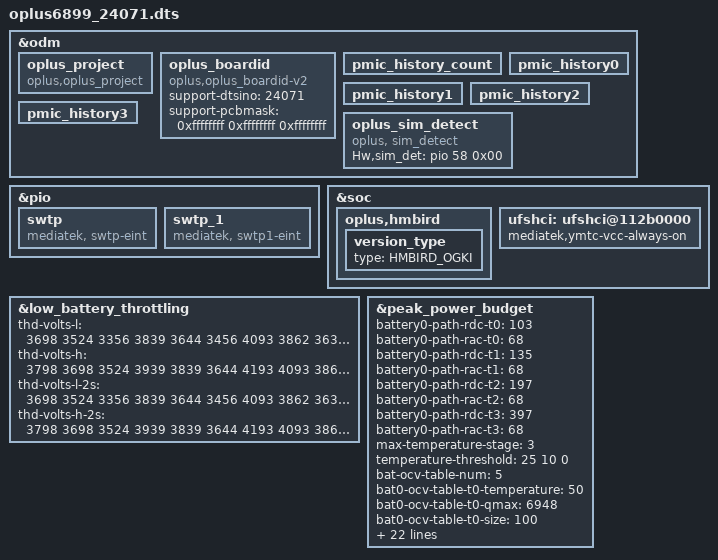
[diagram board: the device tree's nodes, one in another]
// SPDX-License-Identifier: (GPL-2.0 OR MIT)
/*
 * Copyright (C) 2022 MediaTek Inc.
 */
#include "k6899v1_64.dts"

/* #ifdef OPLUS_FEATURE_CHG_BASIC */
/* Add for 24P charge device-tree */
#include "mediatek/oplus_chg/oplus_charge_24071.dtsi"
/* #endif */

/* #ifdef OPLUS_FEATURE_CHG_BASIC */
#include "mediatek/oplus_misc_24071.dtsi"
/* #endif */

/* #ifdef OPLUS_FEATURE_SENSOR */
#include "mediatek/oplus_sensor_24071.dtsi"
/* #endif */

/* #ifdef OPLUS_DISPLAY_FEATURE */
#include "mediatek/oplus-display/mt6899-zhuque-24071-display-overlay.dtsi"
/* #endif */

/* Add for ZhuqueC1 pt device-tree */
#include "mediatek/oplus_pt_24071.dtsi"
/* #endif */

&odm {
	/*OPLUS_FEATURE_OEM_OCDT oppo project start */
	oplus_project:oplus_project {
		compatible = "oplus,oplus_project";
    };

    oplus_boardid:oplus_boardid {
        compatible = "oplus,oplus_boardid-v2";
        support-dtsino=<24071>;//only one u32
        /*first one is low 32bit, last one is highest 32bit, must be 32-bit for 4gpios*/
        support-pcbmask=<0xffffffff 0xffffffff 0xffffffff>;
    };

	pmic_history_count:pmic_history_count {
	};
	pmic_history0:pmic_history0 {
	};
	pmic_history1:pmic_history1 {
	};
	pmic_history2:pmic_history2 {
	};
	pmic_history3:pmic_history3 {
	};
};

&odm {
/* Add for sim detect */
    oplus_sim_detect {
        compatible = "oplus, sim_detect";
        Hw,sim_det = <&pio 58 0x00>;
    };
};

&pio {
	//#ifdef OPLUS_VENDOR_SWTP
	swtp: swtp {
		compatible = "mediatek, swtp-eint";
	};
	 swtp_1: swtp_1 {
        compatible = "mediatek, swtp1-eint";
    };
	//#endif  /*OPLUS_VENDOR_SWTP*/
};

&soc {
    //#ifdef CONFIG_HMBIRD_SCHED
    oplus,hmbird {
        version_type {
            type = "HMBIRD_OGKI";
        };
    };
    //#endif /* CONFIG_HMBIRD_SCHED */
};

&low_battery_throttling {
	thd-volts-l = <
			3698 3524 3356
			3839 3644 3456
			4093 3862 3636
			4400 4139 3784>;
	thd-volts-h = <
			3798 3698 3524
			3939 3839 3644
			4193 4093 3862
			4500 4400 4139>;
	thd-volts-l-2s = <
			3698 3524 3356
			3839 3644 3456
			4093 3862 3636
			4400 4139 3784>;
	thd-volts-h-2s = <
			3798 3698 3524
			3939 3839 3644
			4193 4093 3862
			4500 4400 4139>;
};

&peak_power_budget {
	battery0-path-rdc-t0 = <103>;
	battery0-path-rac-t0 = <68>;
	battery0-path-rdc-t1 = <135>;
	battery0-path-rac-t1 = <68>;
	battery0-path-rdc-t2 = <197>;
	battery0-path-rac-t2 = <68>;
	battery0-path-rdc-t3 = <397>;
	battery0-path-rac-t3 = <68>;
	max-temperature-stage = <3>;
	temperature-threshold = <25 10 0>;

	bat-ocv-table-num = <5>;

	bat0-ocv-table-t0-temperature = <50>;
	bat0-ocv-table-t0-qmax = <6948>;
	bat0-ocv-table-t0-size = <100>;
	bat0-ocv-table-t0 = <
		0       44828   0
		719     44597   0
		1438    44430   0
		2156    44298   0
		2875    44184   0
		3594    44074   0
		4313    43968   0
		5031    43860   0
		5750    43754   0
		6469    43642   0
		7188    43530   0
		7906    43418   0
		8625    43300   0
		9344    43184   0
		10063   43065   0
		10781   42937   0
		11500   42816   0
		12219   42688   0
		12938   42561   0
		13656   42434   0
		14375   42306   0
		15094   42171   0
		15813   42042   0
		16531   41914   0
		17250   41786   0
		17969   41664   0
		18688   41537   0
		19407   41418   0
		20125   41298   0
		20844   41173   0
		21563   41057   0
		22282   40941   0
		23000   40830   0
		23719   40718   0
		24438   40605   0
		25157   40495   0
		25875   40392   0
		26594   40288   0
		27313   40186   0
		28032   40092   0
		28750   39992   0
		29469   39894   0
		30188   39787   0
		30907   39660   0
		31625   39488   0
		32344   39330   0
		33063   39220   0
		33782   39128   0
		34501   39049   0
		35219   38971   0
		35938   38896   0
		36657   38826   0
		37376   38767   0
		38094   38705   0
		38813   38643   0
		39532   38583   0
		40251   38526   0
		40969   38476   0
		41688   38421   0
		42407   38372   0
		43126   38326   0
		43844   38278   0
		44563   38237   0
		45282   38193   0
		46001   38155   0
		46719   38114   0
		47438   38078   0
		48157   38041   0
		48876   37995   0
		49594   37950   0
		50313   37868   0
		51032   37779   0
		51751   37704   0
		52470   37655   0
		53188   37599   0
		53907   37544   0
		54626   37490   0
		55345   37444   0
		56063   37395   0
		56782   37351   0
		57501   37302   0
		58220   37235   0
		58938   37159   0
		59657   37092   0
		60376   37025   0
		61095   36933   0
		61813   36875   0
		62532   36859   0
		63251   36848   0
		63970   36826   0
		64688   36808   0
		65407   36767   0
		66126   36619   0
		66845   36235   0
		67564   35698   0
		68282   34998   0
		69001   34011   0
		69720   32471   0
		70439   32471   0
		71157   32471   0>;

	bat0-ocv-table-t1-temperature = <25>;
	bat0-ocv-table-t1-qmax = <7090>;
	bat0-ocv-table-t1-size = <100>;
	bat0-ocv-table-t1 = <
		0       44934   0
		719     44701   0
		1438    44536   0
		2156    44405   0
		2875    44289   0
		3594    44185   0
		4313    44078   0
		5031    43962   0
		5750    43856   0
		6469    43751   0
		7188    43639   0
		7906    43529   0
		8625    43412   0
		9344    43310   0
		10063   43193   0
		10781   43069   0
		11500   42946   0
		12219   42820   0
		12938   42695   0
		13656   42566   0
		14375   42438   0
		15094   42310   0
		15813   42179   0
		16531   42048   0
		17250   41927   0
		17969   41799   0
		18688   41669   0
		19407   41548   0
		20125   41422   0
		20844   41303   0
		21563   41187   0
		22282   41068   0
		23000   40951   0
		23719   40843   0
		24438   40728   0
		25157   40622   0
		25875   40513   0
		26594   40409   0
		27313   40309   0
		28032   40202   0
		28750   40102   0
		29469   40002   0
		30188   39901   0
		30907   39793   0
		31625   39673   0
		32344   39523   0
		33063   39361   0
		33782   39229   0
		34501   39130   0
		35219   39039   0
		35938   38967   0
		36657   38896   0
		37376   38830   0
		38094   38767   0
		38813   38706   0
		39532   38650   0
		40251   38590   0
		40969   38536   0
		41688   38485   0
		42407   38434   0
		43126   38389   0
		43844   38345   0
		44563   38297   0
		45282   38257   0
		46001   38218   0
		46719   38185   0
		47438   38147   0
		48157   38108   0
		48876   38078   0
		49594   38044   0
		50313   38001   0
		51032   37967   0
		51751   37923   0
		52470   37871   0
		53188   37815   0
		53907   37770   0
		54626   37716   0
		55345   37662   0
		56063   37614   0
		56782   37580   0
		57501   37535   0
		58220   37493   0
		58938   37441   0
		59657   37373   0
		60376   37307   0
		61095   37232   0
		61813   37163   0
		62532   37070   0
		63251   37007   0
		63970   36991   0
		64688   36975   0
		65407   36956   0
		66126   36936   0
		66845   36898   0
		67564   36780   0
		68282   36403   0
		69001   35859   0
		69720   35131   0
		70439   34082   0
		71157   32223   0>;

	bat0-ocv-table-t2-temperature = <10>;
	bat0-ocv-table-t2-qmax = <7056>;
	bat0-ocv-table-t2-size = <100>;
	bat0-ocv-table-t2 = <
		0       44822   0
		719     44608   0
		1438    44459   0
		2156    44332   0
		2875    44228   0
		3594    44128   0
		4313    44021   0
		5031    43921   0
		5750    43821   0
		6469    43707   0
		7188    43601   0
		7906    43495   0
		8625    43378   0
		9344    43260   0
		10063   43146   0
		10781   43019   0
		11500   42895   0
		12219   42767   0
		12938   42638   0
		13656   42509   0
		14375   42380   0
		15094   42247   0
		15813   42122   0
		16531   41987   0
		17250   41866   0
		17969   41735   0
		18688   41609   0
		19407   41484   0
		20125   41361   0
		20844   41240   0
		21563   41122   0
		22282   41004   0
		23000   40889   0
		23719   40780   0
		24438   40664   0
		25157   40557   0
		25875   40450   0
		26594   40344   0
		27313   40245   0
		28032   40143   0
		28750   40036   0
		29469   39942   0
		30188   39829   0
		30907   39716   0
		31625   39579   0
		32344   39417   0
		33063   39271   0
		33782   39157   0
		34501   39062   0
		35219   38974   0
		35938   38902   0
		36657   38828   0
		37376   38765   0
		38094   38697   0
		38813   38640   0
		39532   38573   0
		40251   38522   0
		40969   38467   0
		41688   38416   0
		42407   38370   0
		43126   38325   0
		43844   38275   0
		44563   38233   0
		45282   38193   0
		46001   38154   0
		46719   38114   0
		47438   38080   0
		48157   38047   0
		48876   38013   0
		49594   37985   0
		50313   37946   0
		51032   37919   0
		51751   37886   0
		52470   37852   0
		53188   37812   0
		53907   37767   0
		54626   37717   0
		55345   37661   0
		56063   37617   0
		56782   37582   0
		57501   37543   0
		58220   37493   0
		58938   37429   0
		59657   37359   0
		60376   37295   0
		61095   37234   0
		61813   37151   0
		62532   37059   0
		63251   37011   0
		63970   36989   0
		64688   36972   0
		65407   36951   0
		66126   36911   0
		66845   36852   0
		67564   36668   0
		68282   36216   0
		69001   35560   0
		69720   34644   0
		70439   33562   0
		71157   33562   0>;

	bat0-ocv-table-t3-temperature = <0>;
	bat0-ocv-table-t3-qmax = <6803>;
	bat0-ocv-table-t3-size = <100>;
	bat0-ocv-table-t3 = <
		0       44869   0
		719     44628   0
		1438    44472   0
		2156    44353   0
		2875    44248   0
		3594    44150   0
		4313    44056   0
		5031    43958   0
		5750    43858   0
		6469    43758   0
		7188    43652   0
		7906    43543   0
		8625    43433   0
		9344    43317   0
		10063   43201   0
		10781   43084   0
		11500   42958   0
		12219   42833   0
		12938   42705   0
		13656   42578   0
		14375   42450   0
		15094   42319   0
		15813   42188   0
		16531   42060   0
		17250   41932   0
		17969   41806   0
		18688   41679   0
		19407   41554   0
		20125   41429   0
		20844   41308   0
		21563   41187   0
		22282   41068   0
		23000   40950   0
		23719   40837   0
		24438   40720   0
		25157   40609   0
		25875   40500   0
		26594   40390   0
		27313   40284   0
		28032   40181   0
		28750   40072   0
		29469   39963   0
		30188   39846   0
		30907   39721   0
		31625   39606   0
		32344   39444   0
		33063   39306   0
		33782   39188   0
		34501   39086   0
		35219   38997   0
		35938   38916   0
		36657   38841   0
		37376   38771   0
		38094   38706   0
		38813   38641   0
		39532   38582   0
		40251   38524   0
		40969   38469   0
		41688   38415   0
		42407   38365   0
		43126   38316   0
		43844   38270   0
		44563   38223   0
		45282   38184   0
		46001   38139   0
		46719   38100   0
		47438   38063   0
		48157   38028   0
		48876   37994   0
		49594   37962   0
		50313   37930   0
		51032   37901   0
		51751   37876   0
		52470   37845   0
		53188   37817   0
		53907   37787   0
		54626   37741   0
		55345   37705   0
		56063   37659   0
		56782   37611   0
		57501   37572   0
		58220   37524   0
		58938   37467   0
		59657   37397   0
		60376   37325   0
		61095   37257   0
		61813   37184   0
		62532   37088   0
		63251   36995   0
		63970   36945   0
		64688   36904   0
		65407   36861   0
		66126   36799   0
		66845   36707   0
		67564   36513   0
		68282   36259   0
		69001   36259   0
		69720   36259   0
		70439   36259   0
		71157   36259   0>;

	bat-ocv-table-t4-temperature = <(-10)>;
	bat-ocv-table-t4-qmax = <6535>;
	bat-ocv-table-t4-size = <100>;
	bat-ocv-table-t4 = <
		0       44853   0
		719     44575   0
		1438    44397   0
		2156    44258   0
		2875    44146   0
		3594    44034   0
		4313    43933   0
		5031    43833   0
		5750    43732   0
		6469    43631   0
		7188    43524   0
		7906    43418   0
		8625    43311   0
		9344    43195   0
		10063   43083   0
		10781   42971   0
		11500   42848   0
		12219   42725   0
		12938   42602   0
		13656   42473   0
		14375   42349   0
		15094   42221   0
		15813   42091   0
		16531   41966   0
		17250   41835   0
		17969   41711   0
		18688   41582   0
		19407   41458   0
		20125   41335   0
		20844   41212   0
		21563   41089   0
		22282   40972   0
		23000   40853   0
		23719   40733   0
		24438   40612   0
		25157   40499   0
		25875   40388   0
		26594   40268   0
		27313   40152   0
		28032   40036   0
		28750   39914   0
		29469   39786   0
		30188   39652   0
		30907   39521   0
		31625   39392   0
		32344   39275   0
		33063   39164   0
		33782   39062   0
		34501   38969   0
		35219   38885   0
		35938   38807   0
		36657   38734   0
		37376   38657   0
		38094   38594   0
		38813   38535   0
		39532   38474   0
		40251   38418   0
		40969   38366   0
		41688   38308   0
		42407   38256   0
		43126   38207   0
		43844   38138   0
		44563   38099   0
		45282   38058   0
		46001   38015   0
		46719   37998   0
		47438   37964   0
		48157   37924   0
		48876   37897   0
		49594   37866   0
		50313   37844   0
		51032   37821   0
		51751   37798   0
		52470   37771   0
		53188   37745   0
		53907   37711   0
		54626   37678   0
		55345   37633   0
		56063   37576   0
		56782   37519   0
		57501   37480   0
		58220   37416   0
		58938   37343   0
		59657   37269   0
		60376   37192   0
		61095   37111   0
		61813   37010   0
		62532   36903   0
		63251   36824   0
		63970   36754   0
		64688   36697   0
		65407   36607   0
		66126   36607   0
		66845   36607   0
		67564   36607   0
		68282   36607   0
		69001   36607   0
		69720   36607   0
		70439   36607   0
		71157   36607   0>;
};

//&mmlsys1_config {
//	racing-enable;
//};

&soc {
	ufshci: ufshci@112b0000 {
		mediatek,ymtc-vcc-always-on;
	};
};

#include "mediatek/cust_mt6899_zhuquec1_camera_v4l2.dtsi"
#include "mediatek/oplus6899_common.dtsi"
#include <oplus6899_24071/cust.dtsi>
#include "cust_mt6899_24071_audio.dtsi"
#include "mediatek/cust_mt6899_vow_breeno.dtsi"
#include "oplus_tp_24071.dtsi"
/* Add for zhuque C1/S1(24071_24325) fingerprint device-tree */
/* #ifdef CONFIG_UFF_FINGERPRINT */
#include "mediatek/oplus_uff_24071_24325.dtsi"
/* #endif CONFIG_UFF_FINGERPRINT */
//NFC dtsi
#include "mediatek/nfc/mt6899_24071_sn220.dtsi"
//thermal dtsi
#include "mediatek/cust_mt6899_brz_thermal.dtsi"
#include "mediatek/wifi_bt_fem/mt6899_zhuque_fem_vc536411.dtsi"
/*End of this file, DO NOT ADD ANYTHING HERE*/
